# MAIN_SEC_MMR_MAIN_SEC_MMR_CFG1_45A80000h register map
Vendor: Texas Instruments
Peripheral module from a debugger description file (folder am62L).
Registers are 32-bit, read-write, reset 0xF unless marked. A register's access mark holds for its fields unless they carry their own. Offsets are as the file gives them; lines under a group give offsets from that group; [hi:lo] are bit positions; {n}, {i} and the like mark numbered series; 'fields as' and 'values as' point back to an identical list; <NAME> marks a mode.

## MAIN_SEC_MMR_CFG1
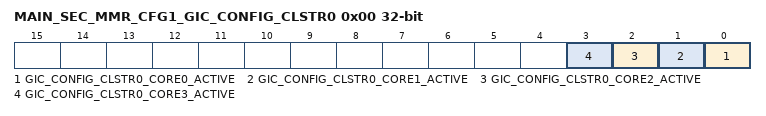
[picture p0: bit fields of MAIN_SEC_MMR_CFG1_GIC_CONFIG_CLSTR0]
0x00 MAIN_SEC_MMR_CFG1_GIC_CONFIG_CLSTR0 — Configures GIC Power Management for Cluster0. Determines whether a core will be routed shared-SPI events that might wake the core.
  [n] GIC_CONFIG_CLSTR0_CORE{n}_ACTIVE (n=0..3) — GICSS cpu_active input for Core{n} of Cluster0Field values (others are reserved):1'b0 - Core is in a software-transparent low power mode, not to receive shared SPIs.1'b1 - Core is active and available for shared SPIs Reset Source: mod_g_rst_n
